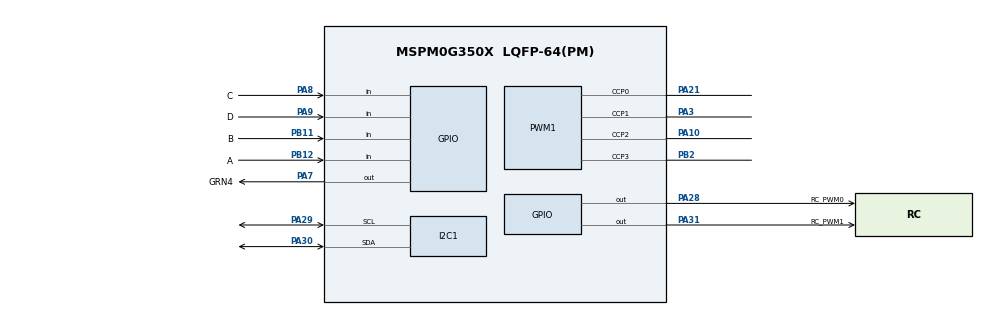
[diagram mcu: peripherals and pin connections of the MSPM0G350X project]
/**
 * @cliArgs --device "MSPM0G350X" --part "Default" --package "LQFP-64(PM)" --product "mspm0_sdk@2.05.01.01"
 * @versions {"tool":"1.24.0+4150"}
 */

/**
 * Import the modules used in this configuration.
 */
const ADC12  = scripting.addModule("/ti/driverlib/ADC12", {}, false);
const ADC121 = ADC12.addInstance();
const ADC122 = ADC12.addInstance();
const GPIO   = scripting.addModule("/ti/driverlib/GPIO", {}, false);
const GPIO1  = GPIO.addInstance();
const GPIO2  = GPIO.addInstance();
const GPIO3  = GPIO.addInstance();
const I2C    = scripting.addModule("/ti/driverlib/I2C", {}, false);
const I2C1   = I2C.addInstance();
const PWM    = scripting.addModule("/ti/driverlib/PWM", {}, false);
const PWM1   = PWM.addInstance();
const SYSCTL = scripting.addModule("/ti/driverlib/SYSCTL");
const TIMER  = scripting.addModule("/ti/driverlib/TIMER", {}, false);
const TIMER1 = TIMER.addInstance();

/**
 * Write custom configuration values to the imported modules.
 */
const divider7       = system.clockTree["PLL_PDIV"];
divider7.divideValue = 4;

const divider9       = system.clockTree["UDIV"];
divider9.divideValue = 2;

const multiplier2         = system.clockTree["PLL_QDIV"];
multiplier2.multiplyValue = 10;

const mux8       = system.clockTree["HSCLKMUX"];
mux8.inputSelect = "HSCLKMUX_SYSPLL2X";

ADC121.$name                      = "ADC12_0";
ADC121.sampClkDiv                 = "DL_ADC12_CLOCK_DIVIDE_48";
ADC121.repeatMode                 = true;
ADC121.adcMem0_name               = "TEMP_M1";
ADC121.adcMem0chansel             = "DL_ADC12_INPUT_CHAN_1";
ADC121.adcMem1_name               = "CURR_M1";
ADC121.adcMem1chansel             = "DL_ADC12_INPUT_CHAN_3";
ADC121.sampleTime0                = "10 ms";
ADC121.enabledInterrupts          = ["DL_ADC12_INTERRUPT_MEM0_RESULT_LOADED","DL_ADC12_INTERRUPT_MEM1_RESULT_LOADED"];
ADC121.interruptPriority          = "2";
ADC121.samplingOperationMode      = "sequence";
ADC121.endAdd                     = 1;
ADC121.adcPin1Config.$name        = "ti_driverlib_gpio_GPIOPinGeneric9";
ADC121.peripheral.$assign         = "ADC0";
ADC121.peripheral.adcPin1.$assign = "PA26";
ADC121.adcPin3Config.$name        = "ti_driverlib_gpio_GPIOPinGeneric8";

ADC122.$name                      = "ADC12_1";
ADC122.sampClkDiv                 = "DL_ADC12_CLOCK_DIVIDE_48";
ADC122.repeatMode                 = true;
ADC122.adcMem0_name               = "TEMP_M0";
ADC122.adcMem1_name               = "CURR_M0";
ADC122.adcMem1chansel             = "DL_ADC12_INPUT_CHAN_1";
ADC122.adcMem2_name               = "VS1";
ADC122.adcMem2chansel             = "DL_ADC12_INPUT_CHAN_2";
ADC122.sampleTime0                = "10 ms";
ADC122.enabledInterrupts          = ["DL_ADC12_INTERRUPT_MEM0_RESULT_LOADED","DL_ADC12_INTERRUPT_MEM1_RESULT_LOADED","DL_ADC12_INTERRUPT_MEM2_RESULT_LOADED"];
ADC122.interruptPriority          = "2";
ADC122.samplingOperationMode      = "sequence";
ADC122.endAdd                     = 2;
ADC122.adcPin0Config.$name        = "ti_driverlib_gpio_GPIOPinGeneric10";
ADC122.peripheral.$assign         = "ADC1";
ADC122.peripheral.adcPin0.$assign = "PA15";
ADC122.adcPin1Config.$name        = "ti_driverlib_gpio_GPIOPinGeneric11";
ADC122.adcPin2Config.$name        = "ti_driverlib_gpio_GPIOPinGeneric12";

const Board = scripting.addModule("/ti/driverlib/Board", {}, false);

GPIO1.$name                         = "GPIO";
GPIO1.port                          = "PORTA";
GPIO1.associatedPins.create(3);
GPIO1.associatedPins[0].$name       = "GRN4";
GPIO1.associatedPins[0].pin.$assign = "PA7";
GPIO1.associatedPins[1].$name       = "RC_PWM0";
GPIO1.associatedPins[1].pin.$assign = "PA28";
GPIO1.associatedPins[2].$name       = "RC_PWM1";
GPIO1.associatedPins[2].pin.$assign = "PA31";

GPIO2.$name                         = "QUAD_M0";
GPIO2.port                          = "PORTB";
GPIO2.portSegment                   = "Lower";
GPIO2.associatedPins.create(2);
GPIO2.associatedPins[0].direction   = "INPUT";
GPIO2.associatedPins[0].$name       = "A";
GPIO2.associatedPins[0].pin.$assign = "PB12";
GPIO2.associatedPins[1].$name       = "B";
GPIO2.associatedPins[1].direction   = "INPUT";
GPIO2.associatedPins[1].pin.$assign = "PB11";

GPIO3.$name                         = "QUAD_M1";
GPIO3.port                          = "PORTA";
GPIO3.portSegment                   = "Lower";
GPIO3.associatedPins.create(2);
GPIO3.associatedPins[0].direction   = "INPUT";
GPIO3.associatedPins[0].$name       = "C";
GPIO3.associatedPins[0].pin.$assign = "PA8";
GPIO3.associatedPins[1].$name       = "D";
GPIO3.associatedPins[1].direction   = "INPUT";
GPIO3.associatedPins[1].pin.$assign = "PA9";

I2C1.$name                             = "I2C1";
I2C1.basicEnableController             = true;
I2C1.basicControllerStandardBusSpeed   = "Fast";
I2C1.interruptPriority                 = "2";
I2C1.intController                     = ["ARBITRATION_LOST","NACK","RXFIFO_TRIGGER","RX_DONE","TX_DONE"];
I2C1.peripheral.$assign                = "I2C1";
I2C1.peripheral.sdaPin.$assign         = "PA30";
I2C1.peripheral.sclPin.$assign         = "PA29";
I2C1.sdaPinConfig.$name                = "ti_driverlib_gpio_GPIOPinGeneric13";
I2C1.sdaPinConfig.hideOutputInversion  = scripting.forceWrite(false);
I2C1.sdaPinConfig.onlyInternalResistor = scripting.forceWrite(false);
I2C1.sdaPinConfig.passedPeripheralType = scripting.forceWrite("Digital");
I2C1.sclPinConfig.$name                = "ti_driverlib_gpio_GPIOPinGeneric14";
I2C1.sclPinConfig.hideOutputInversion  = scripting.forceWrite(false);
I2C1.sclPinConfig.onlyInternalResistor = scripting.forceWrite(false);
I2C1.sclPinConfig.passedPeripheralType = scripting.forceWrite("Digital");

PWM1.$name                           = "PWM_0";
PWM1.pwmMode                         = "CENTER_ALIGN";
PWM1.dutyArgs                        = "[50,0,0,0]";
PWM1.deadBandEn                      = true;
PWM1.ccIndex                         = [0,1,2,3];
PWM1.ccIndexCmpl                     = [0,1,2,3];
PWM1.timerCount                      = 200;
PWM1.clockPrescale                   = 40;
PWM1.dbRiseDelayTimerCount           = 1;
PWM1.dbInsertionMode                 = "Mode1";
PWM1.timerStartTimer                 = true;
PWM1.dbFallDelayTimerCount           = 1;
PWM1.PWM_CHANNEL_0.$name             = "ti_driverlib_pwm_PWMTimerCC0";
PWM1.PWM_CHANNEL_0.dutyCycle         = 5;
PWM1.PWM_CHANNEL_1.$name             = "ti_driverlib_pwm_PWMTimerCC1";
PWM1.PWM_CHANNEL_1.dutyCycle         = 5;
PWM1.ccp0PinConfig.$name             = "ti_driverlib_gpio_GPIOPinGeneric0";
PWM1.ccp1PinConfig.$name             = "ti_driverlib_gpio_GPIOPinGeneric2";
PWM1.PWM_CHANNEL_2.$name             = "ti_driverlib_pwm_PWMTimerCC2";
PWM1.PWM_CHANNEL_2.dutyCycle         = 5;
PWM1.PWM_CHANNEL_3.$name             = "ti_driverlib_pwm_PWMTimerCC3";
PWM1.PWM_CHANNEL_3.dutyCycle         = 5;
PWM1.ccp2PinConfig.$name             = "ti_driverlib_gpio_GPIOPinGeneric3";
PWM1.ccp3PinConfig.$name             = "ti_driverlib_gpio_GPIOPinGeneric4";
PWM1.peripheral.$assign              = "TIMA0";
PWM1.peripheral.ccp0Pin.$assign      = "PA21";
PWM1.peripheral.ccp0Pin_cmpl.$assign = "PA22";
PWM1.peripheral.ccp1Pin.$assign      = "PA3";
PWM1.peripheral.ccp1Pin_cmpl.$assign = "PA4";
PWM1.peripheral.ccp2Pin.$assign      = "PA10";
PWM1.peripheral.ccp2Pin_cmpl.$assign = "PA11";
PWM1.peripheral.ccp3Pin.$assign      = "PB2";
PWM1.peripheral.ccp3Pin_cmpl.$assign = "PB3";
PWM1.ccp0Pin_cmplConfig.$name        = "ti_driverlib_gpio_GPIOPinGeneric1";
PWM1.ccp1Pin_cmplConfig.$name        = "ti_driverlib_gpio_GPIOPinGeneric5";
PWM1.ccp2Pin_cmplConfig.$name        = "ti_driverlib_gpio_GPIOPinGeneric6";
PWM1.ccp3Pin_cmplConfig.$name        = "ti_driverlib_gpio_GPIOPinGeneric7";

SYSCTL.forceDefaultClkConfig = true;
SYSCTL.clockTreeEn           = true;
SYSCTL.VDD                   = 3.6;

TIMER1.$name              = "TIMER_0";
TIMER1.timerClkDiv        = 8;
TIMER1.timerMode          = "PERIODIC";
TIMER1.timerPeriod        = "1 ms";
TIMER1.timerStartTimer    = true;
TIMER1.interrupts         = ["ZERO"];
TIMER1.interruptPriority  = "2";
TIMER1.peripheral.$assign = "TIMG0";

/**
 * Pinmux solution for unlocked pins/peripherals. This ensures that minor changes to the automatic solver in a future
 * version of the tool will not impact the pinmux you originally saw.  These lines can be completely deleted in order to
 * re-solve from scratch.
 */
ADC121.peripheral.adcPin3.$suggestSolution = "PA24";
ADC122.peripheral.adcPin1.$suggestSolution = "PA16";
ADC122.peripheral.adcPin2.$suggestSolution = "PA17";
Board.peripheral.$suggestSolution          = "DEBUGSS";
Board.peripheral.swclkPin.$suggestSolution = "PA20";
Board.peripheral.swdioPin.$suggestSolution = "PA19";
